# R7FA6M5BH register map
Vendor: Renesas Electronics Corporation; Series: RA6; File version: 1.20.01
CPU: CM33 r0p4, little endian, MPU, FPU, VTOR, 4 interrupt priority bits, 96 interrupts
Registers are 32-bit, read-write, reset 0x0 unless marked. A register's access mark holds for its fields unless they carry their own. Offsets are from the block's base; [hi:lo] are bit positions; {n}, {i} and the like mark numbered series; 'fields as' and 'values as' point back to an identical list.

## CANFD (part 1 of 2)
Base 0x400B0000
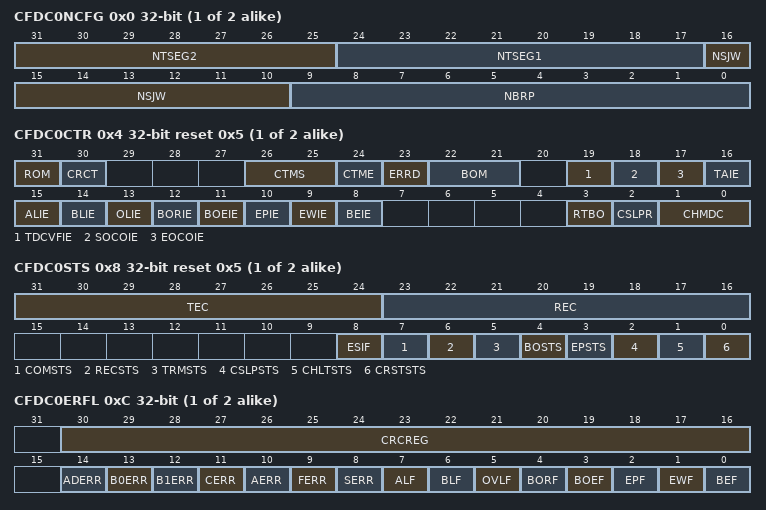
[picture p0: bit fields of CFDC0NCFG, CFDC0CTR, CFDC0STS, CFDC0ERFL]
{0x0+0x10*i} CFDC{i}NCFG (i=0..1) — Channel {i} Nominal Bitrate Configuration Register
  [31:25] NTSEG2 — Timing Segment 2
  [24:17] NTSEG1 — Timing Segment 1
  [16:10] NSJW — Resynchronization Jump Width
  [9:0] NBRP — Channel Nominal Baud Rate Prescaler
{0x4+0x10*i} CFDC{i}CTR (i=0..1) reset 0x5 — Channel {i} Control Registers
  [31] ROM — Restricted Operation Mode
    0=Restricted operation mode disabled; 1=Restricted operation mode enabled
  [30] CRCT — CRC Error Test
    0=First data bit of reception stream not inverted; 1=First data bit of reception stream inverted
  [26:25] CTMS — Channel Test Mode Select
    0=Basic test mode; 1=Listen-only mode; 2=Self-test mode 0 (External loopback mode); 3=Self-test mode 1 (Internal loopback mode)
  [24] CTME — Channel Test Mode Enable
    0=Channel test mode disabled; 1=Channel test mode enabled
  [23] ERRD — Channel Error Display
    0=Only the first set of error codes displayed; 1=Accumulated error codes displayed
  [22:21] BOM — Channel Bus-Off Mode
    0=Normal mode (comply with ISO 11898-1); 1=Entry to Halt mode automatically at bus-off start; 2=Entry to Halt mode automatically at bus-off end; 3=Entry to Halt mode (during bus-off recovery period) by software
  [19] TDCVFIE — Transceiver Delay Compensation Violation Interrupt Enable
    0=Transceiver delay compensation violation interrupt disabled; 1=Transceiver delay compensation violation interrupt enabled
  [18] SOCOIE — Successful Occurrence Counter Overflow Interrupt Enable
    0=Successful occurrence counter overflow interrupt disabled; 1=Successful occurrence counter overflow interrupt enabled
  [17] EOCOIE — Error Occurrence Counter Overflow Interrupt Enable
    0=Error occurrence counter overflow interrupt disabled; 1=Error occurrence counter overflow interrupt enabled
  [16] TAIE — Transmission Abort Interrupt Enable
    0=TX abort interrupt disabled; 1=TX abort interrupt enabled
  [15] ALIE — Arbitration Lost Interrupt Enable
    0=Arbitration lost interrupt disabled; 1=Arbitration lost interrupt enabled
  [14] BLIE — Bus Lock Interrupt Enable
    0=Bus lock interrupt disabled; 1=Bus lock interrupt enabled
  [13] OLIE — Overload Interrupt Enable
    0=Overload interrupt disabled; 1=Overload interrupt enabled
  [12] BORIE — Bus-Off Recovery Interrupt Enable
    0=Bus-off recovery interrupt disabled; 1=Bus-off recovery interrupt enabled
  [11] BOEIE — Bus-Off Entry Interrupt Enable
    0=Bus-off entry interrupt disabled; 1=Bus-off entry interrupt enabled
  [10] EPIE — Error Passive Interrupt Enable
    0=Error passive interrupt disabled; 1=Error passive interrupt enabled
  [9] EWIE — Error Warning Interrupt Enable
    0=Error warning interrupt disabled; 1=Error warning interrupt enabled
  [8] BEIE — Bus Error Interrupt Enable
    0=Bus error interrupt disabled; 1=Bus error interrupt enabled
  [3] RTBO — Return from Bus-Off
    0=Channel is not forced to return from bus-off; 1=Channel is forced to return from bus-off
  [2] CSLPR — Channel Sleep Request
    0=Channel sleep request disabled; 1=Channel sleep request enabled
  [1:0] CHMDC — Channel Mode Control
    0=Channel operation mode request; 1=Channel reset request; 2=Channel halt request; 3=Keep current value
{0x8+0x10*i} CFDC{i}STS (i=0..1) reset 0x5 — Channel {i} Status Registers
  [31:24] TEC ro — Transmission Error Count
  [23:16] REC ro — Reception Error Count
  [8] ESIF — Error State Indication Flag
    0=No CANFD message has been received when the ESI flag was set; 1=At least one CANFD message was received when the ESI flag was set
  [7] COMSTS ro — Channel Communication Status
    0=Channel is not ready for communication; 1=Channel is ready for communication
  [6] RECSTS ro — Channel Receive Status
    0=Channel is not receiving; 1=Channel is receiving
  [5] TRMSTS ro — Channel Transmit Status
    0=Channel is not transmitting; 1=Channel is transmitting
  [4] BOSTS ro — Channel Bus-Off Status
    0=Channel not in bus-off state; 1=Channel in bus-off state
  [3] EPSTS ro — Channel Error Passive Status
    0=Channel not in error passive state; 1=Channel in error passive state
  [2] CSLPSTS ro — Channel Sleep Status
    0=Channel not in Sleep mode; 1=Channel in Sleep mode
  [1] CHLTSTS ro — Channel Halt Status
    0=Channel not in Halt mode; 1=Channel in Halt mode
  [0] CRSTSTS ro — Channel Reset Status
    0=Channel not in Reset mode; 1=Channel in Reset mode
{0xC+0x10*i} CFDC{i}ERFL (i=0..1) — Channel {i} Error Flag Registers
  [30:16] CRCREG ro — CRC Register value
  [14] ADERR — Acknowledge Delimiter Error
    0=Channel acknowledge delimiter error not detected; 1=Channel acknowledge delimiter error detected
  [13] B0ERR — Bit 0 Error
    0=Channel bit 0 error not detected; 1=Channel bit 0 error detected
  [12] B1ERR — Bit 1 Error
    0=Channel bit 1 error not detected; 1=Channel bit 1 error detected
  [11] CERR — CRC Error
    0=Channel CRC error not detected; 1=Channel CRC error detected
  [10] AERR — Acknowledge Error
    0=Channel acknowledge error not detected; 1=Channel acknowledge error detected
  [9] FERR — Form Error
    0=Channel form error not detected; 1=Channel form error detected
  [8] SERR — Stuff Error
    0=Channel stuff error not detected; 1=Channel stuff error detected
  [7] ALF — Arbitration Lost Flag
    0=Channel arbitration lost not detected; 1=Channel arbitration lost detected
  [6] BLF — Bus Lock Flag
    0=Channel bus lock not detected; 1=Channel bus lock detected
  [5] OVLF — Overload Flag
    0=Channel overload not detected; 1=Channel overload detected
  [4] BORF — Bus-Off Recovery Flag
    0=Channel bus-off recovery not detected; 1=Channel bus-off recovery detected
  [3] BOEF — Bus-Off Entry Flag
    0=Channel bus-off entry not detected; 1=Channel bus-off entry detected
  [2] EPF — Error Passive Flag
    0=Channel error passive not detected; 1=Channel error passive detected
  [1] EWF — Error Warning Flag
    0=Channel error warning not detected; 1=Channel error warning detected
  [0] BEF — Bus Error Flag
    0=Channel bus error not detected; 1=Channel bus error detected
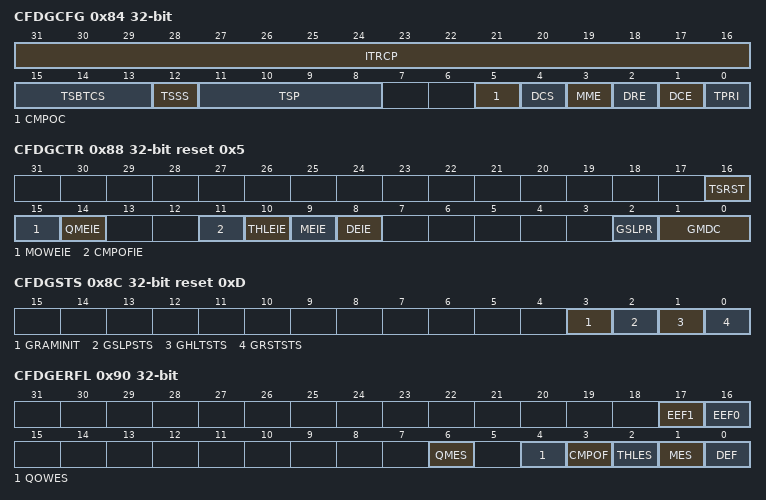
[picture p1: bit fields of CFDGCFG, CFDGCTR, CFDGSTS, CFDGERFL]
0x84 CFDGCFG — Global Configuration Register
  [31:16] ITRCP — Interval Timer Reference Clock Prescaler
  [15:13] TSBTCS — Timestamp Bit Time Channel Select
    0=Select clock from channel 0; 1=Select clock from channel 1; other=Others (Setting prohibited)
  [12] TSSS — Timestamp Source Select
    0=Source clock for timestamp counter is peripheral clock; 1=Source clock for timestamp counter is bit time clock
  [11:8] TSP — Timestamp Prescaler
  [5] CMPOC — CAN-FD Message Payload Overflow Configuration
    0=Message is rejected; 1=Message payload is cut to fit to configured message size
  [4] DCS — Data Link Controller Clock Select
    0=Internal clean clock; 1=External clock source connected to CANMCLK pin
  [3] MME — Mirror Mode Enable
    0=Mirror mode disabled; 1=Mirror mode enabled
  [2] DRE — DLC Replacement Enable
    0=DLC replacement disabled; 1=DLC replacement enabled
  [1] DCE — DLC Check Enable
    0=DLC check disabled; 1=DLC check enabled
  [0] TPRI — Transmission Priority
    0=ID priority; 1=Message buffer number priority
0x88 CFDGCTR reset 0x5 — Global Control Register
  [16] TSRST — Timestamp Reset
    0=Timestamp not reset; 1=Timestamp reset
  [15] MOWEIE — GW FIFO Message Overwrite Error Interrupt Enable
    0=GW FIFO message overwrite error interrupt disabled; 1=GW FIFO message overwrite error interrupt enabled
  [14] QMEIE — TXQ Message Lost Error Interrupt Enable
    0=TXQ message lost error interrupt disabled; 1=TXQ message lost error interrupt enabled
  [11] CMPOFIE — CANFD Message Payload Overflow Flag Interrupt Enable
    0=CANFD message payload overflow flag interrupt disabled; 1=CANFD message payload overflow flag interrupt enabled
  [10] THLEIE — TX History List Entry Lost Interrupt Enable
    0=TX history list entry lost interrupt disabled; 1=TX history list entry lost interrupt enabled
  [9] MEIE — Message Lost Error Interrupt Enable
    0=Message lost error interrupt disabled; 1=Message lost error interrupt enabled
  [8] DEIE — DLC Check Interrupt Enable
    0=DLC check interrupt disabled; 1=DLC check interrupt enabled
  [2] GSLPR — Global Sleep Request
    0=Global sleep request disabled; 1=Global sleep request enabled
  [1:0] GMDC — Global Mode Control
    0=Global operation mode request; 1=Global reset mode request; 2=Global halt mode request; 3=Keep current value
0x8C CFDGSTS ro reset 0xD — Global Status Register
  [3] GRAMINIT — Global RAM Initialization
    0=RAM initialization is complete; 1=RAM initialization is ongoing
  [2] GSLPSTS — Global Sleep Status
    0=Not in Sleep mode; 1=In Sleep mode
  [1] GHLTSTS — Global Halt Status
    0=Not in Halt mode; 1=In Halt mode
  [0] GRSTSTS — Global Reset Status
    0=Not in Reset mode; 1=In Reset mode
0x90 CFDGERFL — Global Error Flag Register
  [17] EEF1 — ECC Error Flag for Channel 1
    0=ECC error not detected during TX-SCAN; 1=ECC error detected during TX-SCAN
  [16] EEF0 — ECC Error Flag for Channel 0
    values as EEF1
  [6] QMES ro — TXQ Message Lost Error Status
    0=TXQ message lost error not detected; 1=TXQ message lost error detected
  [4] QOWES ro — TXQ Message Overwrite Error Status
    0=TXQ message overwrite error not detected; 1=TXQ message overwrite error detected
  [3] CMPOF — CANFD Message Payload Overflow Flag
    0=CANFD message payload overflow not detected; 1=CANFD message payload overflow detected
  [2] THLES ro — TX History List Entry Lost Error Status
    0=TX history list entry lost error not detected; 1=TX history list entry lost error detected
  [1] MES ro — Message Lost Error Status
    0=Message lost error not detected; 1=Message lost error detected
  [0] DEF — DLC Error Flag
    0=DLC error not detected; 1=DLC error detected
0x94 CFDGTSC ro — Global Timestamp Counter Register
  [15:0] TS — Timestamp value
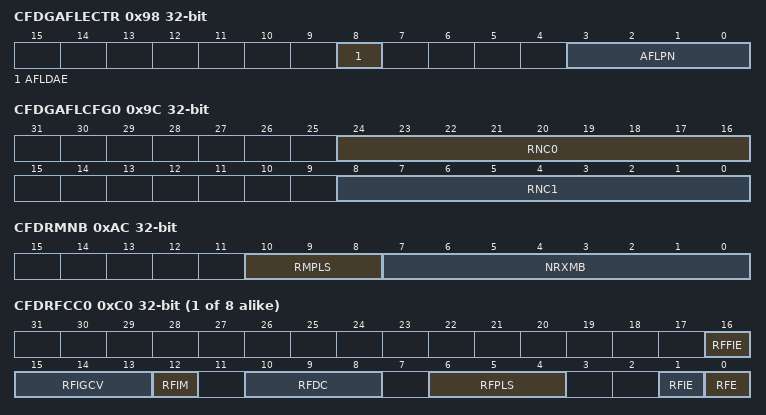
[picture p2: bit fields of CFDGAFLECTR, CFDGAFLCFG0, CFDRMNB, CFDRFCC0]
0x98 CFDGAFLECTR — Global Acceptance Filter List Entry Control Register
  [8] AFLDAE — Acceptance Filter List Data Access Enable
    0=Acceptance Filter List data access disabled; 1=Acceptance Filter List data access enabled
  [3:0] AFLPN — Acceptance Filter List Page Number
0x9C CFDGAFLCFG0 — Global Acceptance Filter List Configuration Register 0
  [24:16] RNC0 — Rule Number for Channel 0
  [8:0] RNC1 — Rule Number for Channel 1
0xAC CFDRMNB — RX Message Buffer Number Register
  [10:8] RMPLS — Reception Message Buffer Payload Data Size
    0=8 bytes; 1=12 bytes; 2=16 bytes; 3=20 bytes; 4=24 bytes; 5=32 bytes; 6=48 bytes; 7=64 bytes
  [7:0] NRXMB — Number of RX Message Buffers
0xB0 CFDRMND0 — RX Message Buffer New Data Register 0
  [31:0] RMNS — RX Message Buffer New Data Status
    0=New data not stored in corresponding RX message buffer; 1=New data stored in corresponding RX message buffer
{0xC0+4i} CFDRFCC{i} (i=0..7) — RX FIFO Configuration/Control Registers {i}
  [16] RFFIE — RX FIFO Full Interrupt Enable
    0=FIFO interrupt generation disabled; 1=FIFO interrupt generation enabled
  [15:13] RFIGCV — RX FIFO Interrupt Generation Counter Value
    0=Interrupt generated when FIFO is 1/8th full; 1=Interrupt generated when FIFO is 1/4th full; 2=Interrupt generated when FIFO is 3/8th full; 3=Interrupt generated when FIFO is 1/2 full; 4=Interrupt generated when FIFO is 5/8th full; 5=Interrupt generated when FIFO is 3/4th full; 6=Interrupt generated when FIFO is 7/8th full; 7=Interrupt generated when FIFO is full
  [12] RFIM — RX FIFO Interrupt Mode
    0=Interrupt generated when RX FIFO counter reaches RFIGCV value from values smaller than RFIGCV; 1=Interrupt generated at the end of every received message storage
  [10:8] RFDC — RX FIFO Depth Configuration
    0=FIFO Depth = 0 message; 1=FIFO Depth = 4 messages; 2=FIFO Depth = 8 messages; 3=FIFO Depth = 16 messages; 4=FIFO Depth = 32 essages; 5=FIFO Depth = 48 messages; 6=FIFO Depth = 64 messages; 7=FIFO Depth = 128 messages
  [6:4] RFPLS — Rx FIFO Payload Data Size Configuration
    values as CFDRMNB.RMPLS
  [1] RFIE — RX FIFO Interrupt Enable
    values as RFFIE
  [0] RFE — RX FIFO Enable
    0=FIFO disabled; 1=FIFO enabled
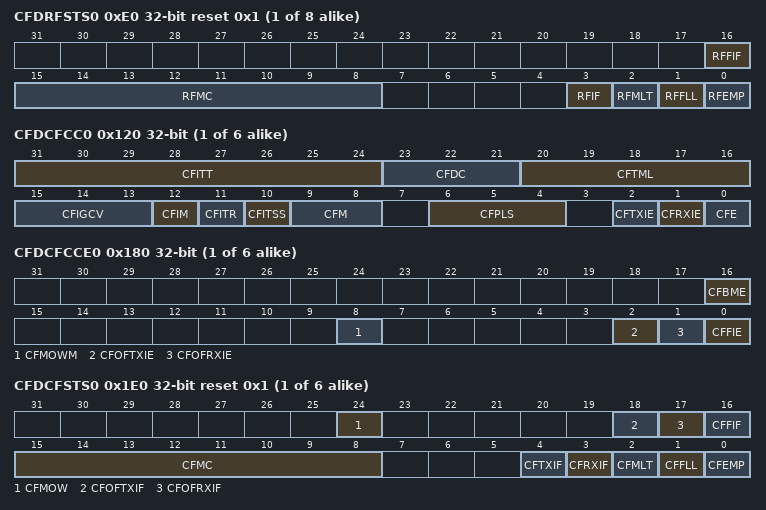
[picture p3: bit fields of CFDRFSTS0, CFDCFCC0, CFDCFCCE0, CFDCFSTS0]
{0xE0+4i} CFDRFSTS{i} (i=0..7) reset 0x1 — RX FIFO Status Registers {i}
  [16] RFFIF — RX FIFO Full Interrupt Flag
    0=FIFO full interrupt condition not satisfied; 1=FIFO full interrupt condition satisfied
  [15:8] RFMC ro — RX FIFO Message Count
  [3] RFIF — RX FIFO Interrupt Flag
    0=FIFO interrupt condition not satisfied; 1=FIFO interrupt condition satisfied
  [2] RFMLT — RX FIFO Message Lost
    0=No message lost in FIFO; 1=FIFO message lost
  [1] RFFLL ro — RX FIFO Full
    0=FIFO not full; 1=FIFO full
  [0] RFEMP ro — RX FIFO Empty
    0=FIFO not empty; 1=FIFO empty
{0x100+4i} CFDRFPCTR{i} (i=0..7) — RX FIFO Pointer Control Registers {i}
  [7:0] RFPC wo — RX FIFO Pointer Control
{0x120+4i} CFDCFCC{i} (i=0..5) — Common FIFO Configuration/Control Registers {i}
  [31:24] CFITT — Common FIFO Interval Transmission Time
  [23:21] CFDC — Common FIFO Depth Configuration
    0=FIFO Depth = 0 messages; 1=FIFO Depth = 4 messages; 2=FIFO Depth = 8 messages; 3=FIFO Depth = 16 messages; 4=FIFO Depth = 32 messages; 5=FIFO Depth = 48 messages; 6=FIFO Depth = 64 messages; 7=FIFO Depth = 128 messages
  [20:16] CFTML — Common FIFO TX Message Buffer Link
  [15:13] CFIGCV — Common FIFO Interrupt Generation Counter Value
    values as CFDRFCC0.RFIGCV
  [12] CFIM — Common FIFO Interrupt Mode
    0=RX FIFO mode: RX interrupt generated when Common FIFO counter reaches CFIGCV value from a lower value TX FIFO mode: TX interrupt generated when Common FIFO transmits the last message successfully GW FIFO mode: For RX interrupt flag: Interrupt generated when FIFO counter increments and reaches the value configured in CFIGCV For TX interrupt flag: Interrupt generated when FIFO transmits the last message successfully; 1=RX FIFO mode: RX interrupt generated at the end of every received message storage TX FIFO mode: interrupt generated for every successfully transmitted message GW FIFO mode: For RX interrupt flag: Interrupt generated when a message is stored in the FIFO For TX interrupt flag: Interrupt generated when a message is successfully transmitted from the FIFO
  [11] CFITR — Common FIFO Interval Timer Resolution
    0=Reference clock period × 1; 1=Reference clock period × 10
  [10] CFITSS — Common FIFO Interval Timer Source Select
    0=Reference clock (× 1 / × 10 period); 1=Bit time clock of related channel (FIFO is linked to fixed channel)
  [9:8] CFM — Common FIFO Mode
    0=RX FIFO mode; 1=TX FIFO mode; 2=CAN – CAN GW FIFO mode
  [6:4] CFPLS — Common FIFO Payload Data Size Configuration
    values as CFDRMNB.RMPLS
  [2] CFTXIE — Common FIFO TX Interrupt Enable
    0=FIFO interrupt generation disabled for Frame TX; 1=FIFO interrupt generation enabled for Frame TX
  [1] CFRXIE — Common FIFO RX Interrupt Enable
    0=FIFO interrupt generation disabled for Frame RX; 1=FIFO interrupt generation enabled for Frame RX
  [0] CFE — Common FIFO Enable
    0=FIFO disabled; 1=FIFO enabled
{0x180+4i} CFDCFCCE{i} (i=0..5) — Common FIFO Configuration/Control Enhancement Registers {i}
  [16] CFBME — Common FIFO Buffering Mode Enable
    0=Transmission from Common FIFO; 1=Transmission halt from Common FIFO
  [8] CFMOWM — Common FIFO Message Overwrite Mode
    0=Message discarded mode; 1=Message overwrite mode
  [2] CFOFTXIE — Common FIFO One Frame Transmission Interrupt Enable
    0=One Frame TX interrupt generation disabled; 1=One Frame TX interrupt generation enabled
  [1] CFOFRXIE — Common FIFO One Frame Reception Interrupt Enable
    0=One Frame RX interrupt generation disabled; 1=One Frame RX interrupt generation enabled
  [0] CFFIE — Common FIFO Full Interrupt Enable
    0=FIFO Interrupt generation disabled; 1=FIFO Interrupt generation enabled
{0x1E0+4i} CFDCFSTS{i} (i=0..5) reset 0x1 — Common FIFO Status Registers {i}
  [24] CFMOW — Common FIFO Message Overwrite
    0=No message overwrite occurred in FIFO; 1=Message overwrite occurred in FIFO
  [18] CFOFTXIF — Common FIFO One Frame Transmission Interrupt Flag
  [17] CFOFRXIF — Common FIFO One Frame Reception Interrupt Flag
  [16] CFFIF — Common FIFO Full Interrupt Flag
    0=Interrupt condition not satisfied for FIFO full interrupt; 1=Interrupt condition satisfied for FIFO full interrupt
  [15:8] CFMC ro — Common FIFO Message Count
  [4] CFTXIF — Common TX FIFO Interrupt Flag
    0=FIFO interrupt condition not satisfied after frame transmission; 1=FIFO Interrupt condition satisfied after frame transmission
  [3] CFRXIF — Common RX FIFO Interrupt Flag
    0=FIFO interrupt condition not satisfied after frame reception; 1=FIFO interrupt condition satisfied after frame reception
  [2] CFMLT — Common FIFO Message Lost
    0=Number of message lost in FIFO; 1=FIFO message lost
  [1] CFFLL ro — Common FIFO Full
    0=FIFO not full; 1=FIFO full
  [0] CFEMP ro — Common FIFO Empty
    0=FIFO not empty; 1=FIFO empty
{0x240+4i} CFDCFPCTR{i} (i=0..5) — Common FIFO Pointer Control Registers {i}
  [7:0] CFPC wo — Common FIFO Pointer Control
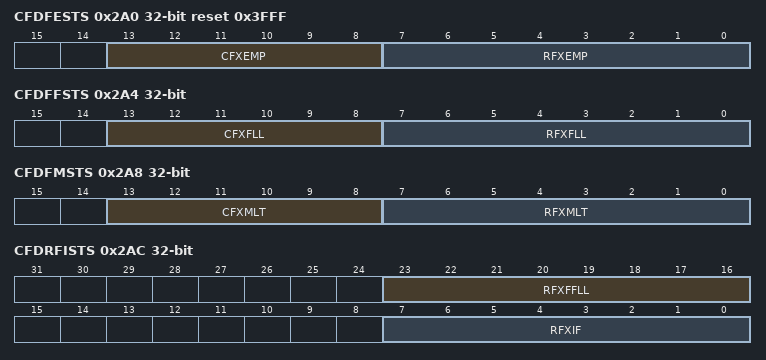
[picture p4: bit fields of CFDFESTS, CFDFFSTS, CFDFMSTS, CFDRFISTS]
0x2A0 CFDFESTS ro reset 0x3FFF — FIFO Empty Status Register
  [13:8] CFXEMP — Common FIFO Empty Status
    0=Corresponding FIFO not empty; 1=Corresponding FIFO empty
  [7:0] RFXEMP — RX FIFO Empty Status
    0=Corresponding FIFO not empty; 1=Corresponding FIFO empty
0x2A4 CFDFFSTS ro — FIFO Full Status Register
  [13:8] CFXFLL — Common FIFO Full Status
    0=Corresponding FIFO not full; 1=Corresponding FIFO full
  [7:0] RFXFLL — RX FIFO Full Status
    0=Corresponding FIFO not full; 1=Corresponding FIFO full
0x2A8 CFDFMSTS ro — FIFO Message Lost Status Register
  [13:8] CFXMLT — Common FIFO Message Lost Status
    0=Corresponding FIFO Message Lost flag not set; 1=Corresponding FIFO Message Lost flag set
  [7:0] RFXMLT — RX FIFO Message Lost Status
    values as CFXMLT
0x2AC CFDRFISTS — RX FIFO Interrupt Flag Status Register
  [23:16] RFXFFLL ro — RX FIFO[x] Interrupt Full Flag Status
    0=Corresponding RX FIFO Interrupt Full flag not set; 1=Corresponding RX FIFO Interrupt Full flag set
  [7:0] RFXIF ro — RX FIFO[x] Interrupt Flag Status
    0=Corresponding RX FIFO Interrupt flag not set; 1=Corresponding RX FIFO Interrupt flag set
0x2B0 CFDCFRISTS — Common FIFO RX Interrupt Flag Status Register
  [5:0] CFXRXIF ro — Common FIFO RX Interrupt Flag Status
    0=Corresponding Common FIFO RX Interrupt flag is not set; 1=Corresponding Common FIFO RX Interrupt flag is set
0x2B4 CFDCFTISTS — Common FIFO TX Interrupt Flag Status Register
  [5:0] CFXTXIF ro — Common FIFO [x] TX Interrupt Flag Status
    0=Corresponding Common FIFO TX Interrupt flag is not set; 1=Corresponding Common FIFO TX Interrupt flag is set
0x2B8 CFDCFOFRISTS ro — Common FIFO One Frame RX Interrupt Flag Status Register
  [5:0] CFXOFRXIF — Common FIFO One Frame RX Interrupt Flag Status
    0=Corresponding Common FIFO One Frame RX Interrupt flag is not set; 1=Corresponding Common FIFO One Frame RX Interrupt flag is set
0x2BC CFDCFOFTISTS ro — Common FIFO One Frame TX Interrupt Flag Status Register
  [5:0] CFXOFTXIF — Common FIFO One Frame TX Interrupt Flag Status
    0=Corresponding Common FIFO One Frame TX Interrupt flag is not set; 1=Corresponding Common FIFO One Frame TX Interrupt flag is set
0x2C0 CFDCFMOWSTS ro — Common FIFO Message Over Write Status Register
  [5:0] CFXMOW — Common FIFO Massage Overwrite Status
    0=Corresponding FIFO Overwrite flag is not set; 1=Corresponding FIFO Overwrite flag is set
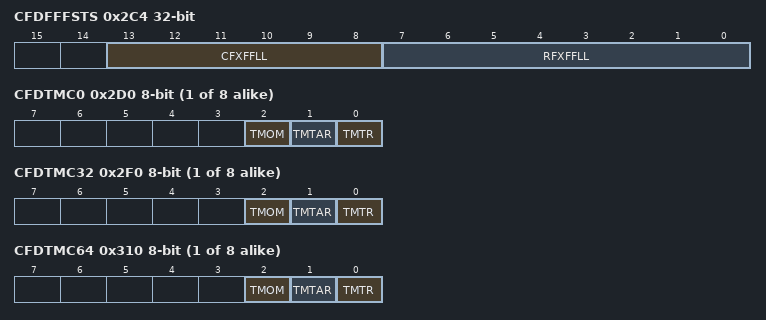
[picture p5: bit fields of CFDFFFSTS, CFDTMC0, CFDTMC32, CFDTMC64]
0x2C4 CFDFFFSTS ro — FIFO FDC Full Status Register
  [13:8] CFXFFLL — COMMON FIFO FDC Level Full Status
    0=Corresponding FIFO full interrupt not set; 1=Corresponding FIFO full interrupt is set
  [7:0] RFXFFLL — RX FIFO FDC Level Full Status
    values as CFXFFLL
{0x2D0+i} CFDTMC{i} (i=0..7) 8-bit — TX Message Buffer Control Registers {i}
  [2] TMOM — TX Message Buffer One-shot Mode
    0=TX message buffer not configured in one-shot mode; 1=TX message buffer configured in one-shot mode
  [1] TMTAR — TX Message Buffer Transmission Abort Request
    0=TX message buffer transmission request abort not requested; 1=TX message buffer transmission request abort requested
  [0] TMTR — TX Message Buffer Transmission Request
    0=TX Message buffer transmission not requested; 1=TX message buffer transmission requested
{0x2D0+i} CFDTMC{i} (i=32..39) 8-bit — TX Message Buffer Control Registers {i}
  fields as CFDTMC0
{0x2D0+i} CFDTMC{i} (i=64..71) 8-bit — TX Message Buffer Control Registers {i}
  fields as CFDTMC0
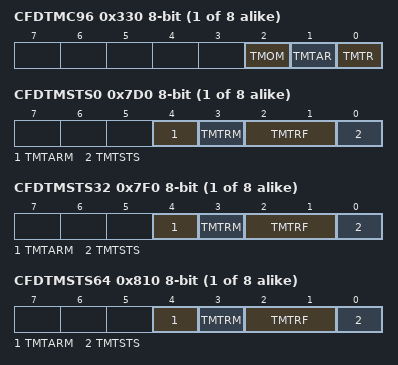
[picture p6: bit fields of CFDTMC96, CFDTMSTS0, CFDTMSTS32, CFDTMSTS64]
{0x2D0+i} CFDTMC{i} (i=96..103) 8-bit — TX Message Buffer Control Registers {i}
  fields as CFDTMC0
{0x7D0+i} CFDTMSTS{i} (i=0..7) 8-bit — TX Message Buffer Status Registers {i}
  [4] TMTARM ro — TX Message Buffer Transmission Abort Request Mirrored
    values as CFDTMC0.TMTAR
  [3] TMTRM ro — TX Message Buffer Transmission Request Mirrored
    0=TX message buffer transmission not requested; 1=TX message buffer transmission requested
  [2:1] TMTRF — TX Message Buffer Transmission Result Flag
    0=No result; 1=Transmission aborted from the TX message buffer; 2=Transmission successful from the TX message buffer and transmission abort was not requested; 3=Transmission successful from the TX message buffer and transmission abort was requested
  [0] TMTSTS ro — TX Message Buffer Transmission Status
    0=No on-going transmission; 1=On-going transmission
{0x7D0+i} CFDTMSTS{i} (i=32..39) 8-bit — TX Message Buffer Status Registers {i}
  fields as CFDTMSTS0
{0x7D0+i} CFDTMSTS{i} (i=64..71) 8-bit — TX Message Buffer Status Registers {i}
  fields as CFDTMSTS0
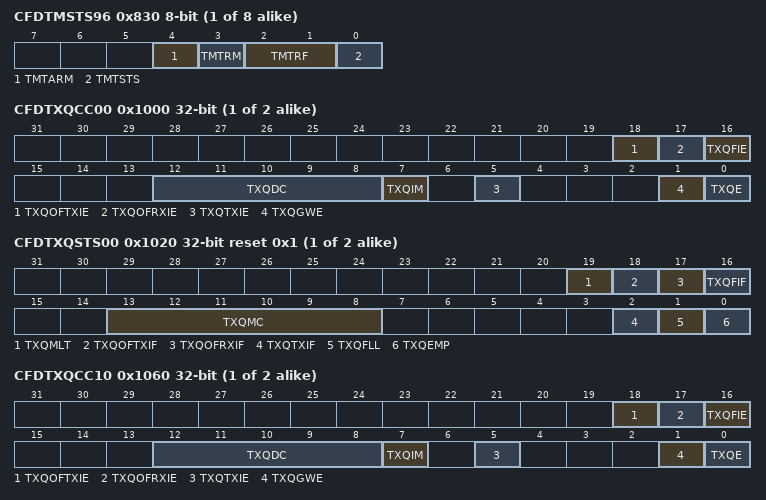
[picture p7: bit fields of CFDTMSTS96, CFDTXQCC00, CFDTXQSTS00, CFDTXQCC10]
{0x7D0+i} CFDTMSTS{i} (i=96..103) 8-bit — TX Message Buffer Status Registers {i}
  fields as CFDTMSTS0
{0xCD0+4i} CFDTMTRSTS{i} (i=0..3) ro — TX Message Buffer Transmission Request Status Register {i}
  [7:0] CFDTMTRSTS — TX Message Buffer Transmission Request Status
    0=Transmission not requested for corresponding TX message buffer; 1=Transmission requested for corresponding TX message buffer
{0xD70+4i} CFDTMTARSTS{i} (i=0..3) ro — TX Message Buffer Transmission Abort Request Status Register {i}
  [7:0] CFDTMTARSTS — TX Message Buffer Transmission Abort Request Status
    0=Transmission abort not requested for corresponding TX message buffer; 1=Transmission abort requested for corresponding TX message buffer
{0xE10+4i} CFDTMTCSTS{i} (i=0..3) ro — TX Message Buffer Transmission Completion Status Register {i}
  [7:0] CFDTMTCSTS — TX Message Buffer Transmission Completion Status
    0=Transmission not complete for corresponding TX message buffer; 1=Transmission completed for corresponding TX message buffer
{0xEB0+4i} CFDTMTASTS{i} (i=0..3) ro — TX Message Buffer Transmission Abort Status Register {i}
  [7:0] CFDTMTASTS — TX Message Buffer Transmission Abort Status
    0=Transmission not aborted for corresponding TX message buffer; 1=Transmission aborted for corresponding TX message buffer
{0xF50+4i} CFDTMIEC{i} (i=0..3) — TX Message Buffer Interrupt Enable Configuration Register {i}
  [7:0] TMIE — TX Message Buffer Interrupt Enable
    0=TX message buffer interrupt disabled for corresponding TX message buffer; 1=TX message buffer interrupt enabled for corresponding TX message buffer
{0x1000+4i} CFDTXQCC0{i} (i=0..1) — TX Queue Configuration/Control Registers 0{i}
  [18] TXQOFTXIE — TXQ One Frame Transmission Interrupt Enable
    values as CFDCFCCE0.CFOFTXIE
  [17] TXQOFRXIE — TXQ One Frame Reception Interrupt Enable
    values as CFDCFCCE0.CFOFRXIE
  [16] TXQFIE — TXQ Full Interrupt Enable
    0=TX Queue full interrupt generation disabled; 1=TX Queue full interrupt generation enabled
  [12:8] TXQDC — TX Queue Depth Configuration
  [7] TXQIM — TX Queue Interrupt Mode
    0=When the last message is successfully transmitted; 1=At every successful transmission
  [5] TXQTXIE — TX Queue TX Interrupt Enable
    0=TX Queue TX interrupt disabled; 1=TX Queue TX interrupt enabled
  [1] TXQGWE — TX Queue Gateway Mode Enable
    0=TX Queue GW mode disabled; 1=TX Queue GW mode enabled
  [0] TXQE — TX Queue Enable
    0=TX Queue disabled; 1=TX Queue enabled
{0x1020+4i} CFDTXQSTS0{i} (i=0..1) reset 0x1 — TX Queue Status Registers 0{i}
  [19] TXQMLT — TXQ Message Lost
    0=No message lost in TXQ; 1=TXQ message lost
  [18] TXQOFTXIF — TXQ One Frame Transmission Interrupt Flag
  [17] TXQOFRXIF — TXQ One Frame Reception Interrupt Flag
  [16] TXQFIF — TXQ Full Interrupt Flag
  [13:8] TXQMC ro — TX Queue Message Count
  [2] TXQTXIF — TX Queue TX Interrupt Flag
    0=TX Queue interrupt condition not satisfied after a frame TX; 1=TX Queue interrupt condition satisfied after a frame TX
  [1] TXQFLL ro — TX Queue Full
    0=TX Queue not full; 1=TX Queue full
  [0] TXQEMP ro — TX Queue Empty
    0=TX Queue not empty; 1=TX Queue empty
{0x1040+4i} CFDTXQPCTR0{i} (i=0..1) — TX Queue Pointer Control Registers 0{i}
  [7:0] TXQPC wo — TX Queue Pointer Control
{0x1060+4i} CFDTXQCC1{i} (i=0..1) — TX Queue Configuration/Control Registers 1{i}
  fields as CFDTXQCC00
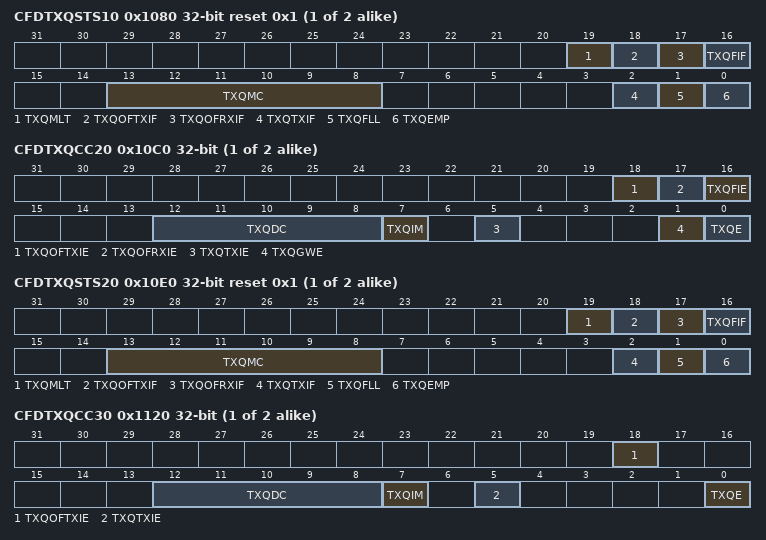
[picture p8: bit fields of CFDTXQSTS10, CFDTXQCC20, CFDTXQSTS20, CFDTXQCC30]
{0x1080+4i} CFDTXQSTS1{i} (i=0..1) reset 0x1 — TX Queue Status Registers 1{i}
  fields as CFDTXQSTS00
{0x10A0+4i} CFDTXQPCTR1{i} (i=0..1) — TX Queue Pointer Control Registers 1{i}
  [7:0] TXQPC wo — TX Queue Pointer Control
{0x10C0+4i} CFDTXQCC2{i} (i=0..1) — TX Queue Configuration/Control Registers 2{i}
  fields as CFDTXQCC00
{0x10E0+4i} CFDTXQSTS2{i} (i=0..1) reset 0x1 — TX Queue Status Registers 2{i}
  fields as CFDTXQSTS00
{0x1100+4i} CFDTXQPCTR2{i} (i=0..1) — TX Queue Pointer Control Registers 2{i}
  [7:0] TXQPC wo — TX Queue Pointer Control
{0x1120+4i} CFDTXQCC3{i} (i=0..1) — TX Queue Configuration/Control Registers 3{i}
  [18] TXQOFTXIE — TXQ One Frame Transmission Interrupt Enable
    values as CFDCFCCE0.CFOFTXIE
  [12:8] TXQDC — TX Queue Depth Configuration
  [7] TXQIM — TX Queue Interrupt Mode
    values as CFDTXQCC00.TXQIM
  [5] TXQTXIE — TX Queue TX Interrupt Enable
    values as CFDTXQCC00.TXQTXIE
  [0] TXQE — TX Queue Enable
    0=TX Queue disabled; 1=TX Queue enabled
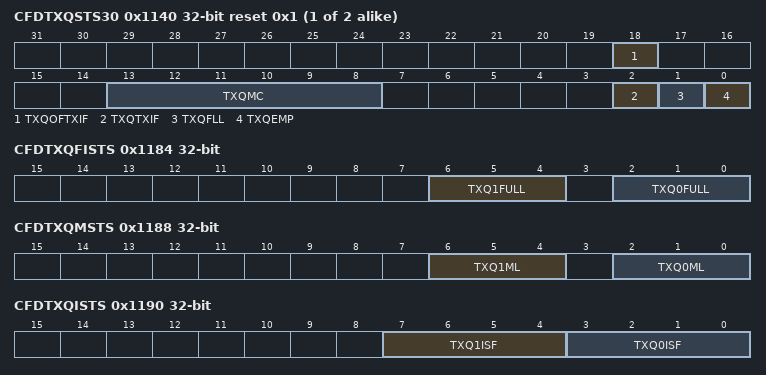
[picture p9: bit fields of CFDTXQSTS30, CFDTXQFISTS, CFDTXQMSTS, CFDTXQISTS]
{0x1140+4i} CFDTXQSTS3{i} (i=0..1) reset 0x1 — TX Queue Status Registers 3{i}
  [18] TXQOFTXIF — TXQ One Frame Transmission Interrupt Flag
  [13:8] TXQMC ro — TX Queue Message Count
  [2] TXQTXIF — TX Queue TX Interrupt Flag
    values as CFDTXQSTS00.TXQTXIF
  [1] TXQFLL ro — TX Queue Full
    0=TX Queue not full; 1=TX Queue full
  [0] TXQEMP ro — TX Queue Empty
    0=TX Queue not empty; 1=TX Queue empty
{0x1160+4i} CFDTXQPCTR3{i} (i=0..1) — TX Queue Pointer Control Registers 3{i}
  [7:0] TXQPC wo — TX Queue Pointer Control
0x1180 CFDTXQESTS ro reset 0xFF — TX Queue Empty Status Register
  [7:0] TXQxEMP — TXQ Empty Status
    0=TXQ not empty; 1=TXQ empty
0x1184 CFDTXQFISTS — TX Queue Full Interrupt Status Register
  [6:4] TXQ1FULL ro — TXQ Full Interrupt Status for Channel 1
    0=TXQ full interrupt is not set; 1=TXQ full interrupt is set
  [2:0] TXQ0FULL ro — TXQ Full Interrupt Status for Channel 0
    0=TXQ full interrupt is not set; 1=TXQ full interrupt is set
0x1188 CFDTXQMSTS — TX Queue Message Lost Status Register
  [6:4] TXQ1ML ro — TXQ Message Lost Status for Channel 1
    0=TXQ message lost flag is not set; 1=TXQ message lost flag is set
  [2:0] TXQ0ML ro — TXQ Message Lost Status for Channel 0
    values as TXQ1ML
0x1190 CFDTXQISTS — TX Queue Interrupt Status Register
  [7:4] TXQ1ISF ro — TXQ Interrupt Status Flag for Channel 1
    0=TXQ Interrupt flag is not set; 1=TXQ Interrupt flag is set
  [3:0] TXQ0ISF ro — TXQ Interrupt Status Flag for Channel 0
    0=TXQ Interrupt flag is not set; 1=TXQ Interrupt flag is set
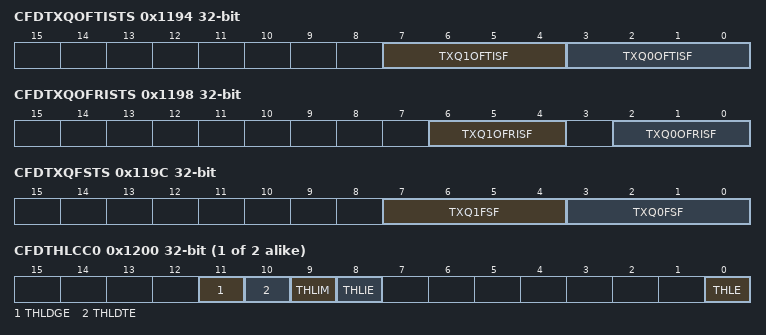
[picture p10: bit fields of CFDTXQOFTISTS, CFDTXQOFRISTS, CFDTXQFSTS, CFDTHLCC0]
0x1194 CFDTXQOFTISTS — TX Queue One Frame TX Interrupt Status Register
  [7:4] TXQ1OFTISF ro — TXQ One Frame TX Interrupt Status Flag for Channel 1
    0=TXQ One Frame TX Interrupt flag is not set; 1=TXQ One Frame TX Interrupt flag is set
  [3:0] TXQ0OFTISF ro — TXQ One Frame TX Interrupt Status Flag for Channel 0
    values as TXQ1OFTISF
0x1198 CFDTXQOFRISTS — TX Queue One Frame RX Interrupt Status Register
  [6:4] TXQ1OFRISF ro — TXQ One Frame RX Interrupt Status Flag
    0=TXQ One Frame RX Interrupt flag is not set; 1=TXQ One Frame RX Interrupt flag is set
  [2:0] TXQ0OFRISF ro — TXQ One Frame RX Interrupt Status Flag
    values as TXQ1OFRISF
0x119C CFDTXQFSTS ro — TX Queue Full Status Register
  [7:4] TXQ1FSF — TXQ Full Status Flag for Channel 1
    0=TXQ Full flag is not set; 1=TXQ Full flag is set
  [3:0] TXQ0FSF — TXQ Full Status Flag for Channel 0
    0=TXQ Full flag is not set; 1=TXQ Full flag is set
{0x1200+4i} CFDTHLCC{i} (i=0..1) — TX History List Configuration/Control Register {i}
  [11] THLDGE — TX History List Dedicated Gateway Enable
    0=Not dedicated Gateway FIFO + Gateway TX Queue; 1=Dedicated Gateway FIFO + Gateway TX Queue
  [10] THLDTE — TX History List Dedicated TX Enable
    0=TX FIFO + TX Queue; 1=Flat TX MB + TX FIFO + TX Queue
  [9] THLIM — TX History List Interrupt Mode
    0=Interrupt generated if TX History List level reaches ¾ of the TX History List depth; 1=Interrupt generated for every successfully stored entry
  [8] THLIE — TX History List Interrupt Enable
    0=TX History List Interrupt disabled; 1=TX History List Interrupt enabled
  [0] THLE — TX History List Enable
    0=TX History List disabled; 1=TX History List enabled
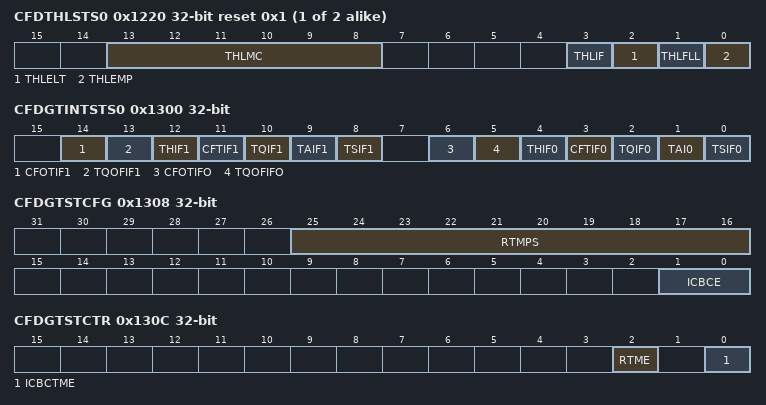
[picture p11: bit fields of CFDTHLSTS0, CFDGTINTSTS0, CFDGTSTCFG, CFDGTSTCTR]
{0x1220+4i} CFDTHLSTS{i} (i=0..1) reset 0x1 — TX History List Status Register {i}
  [13:8] THLMC ro — TX History List Message Count
  [3] THLIF — TX History List Interrupt Flag
    0=TX History List interrupt condition not satisfied; 1=TX History List interrupt condition satisfied
  [2] THLELT — TX History List Entry Lost
    0=No entry lost in TX History List; 1=TX History List entry Lost
  [1] THLFLL ro — TX History List Full
    0=TX History List not full; 1=TX History List full
  [0] THLEMP ro — TX History List Empty
    0=TX History List not empty; 1=TX History List empty
{0x1240+4i} CFDTHLPCTR{i} (i=0..1) — TX History List Pointer Control Registers {i}
  [7:0] THLPC wo — TX History List Pointer Control
0x1300 CFDGTINTSTS0 — Global TX Interrupt Status Register 0
  [14] CFOTIF1 ro — COM FIFO One Frame Transmission Interrupt Flag Channel 1
    0=Channel n COM FIFO One Frame Transmission Interrupt flag not set; 1=Channel n COM FIFO One Frame Transmission Interrupt flag set
  [13] TQOFIF1 ro — TX Queue One Frame Transmission Interrupt Flag Channel 1
    0=Channel n TX Queue One Frame Transmission Interrupt flag not set; 1=Channel n TX Queue One Frame Transmission Interrupt flag set
  [12] THIF1 ro — TX History List Interrupt Channel 1
    0=Channel n TX History List Interrupt flag not set; 1=Channel n TX History List Interrupt flag set
  [11] CFTIF1 ro — COM FIFO TX/GW Mode Interrupt Flag Channel 1
    0=Channel n COM FIFO TX/GW Mode Interrupt flag not set; 1=Channel n COM FIFO TX/GW Mode Interrupt flag set
  [10] TQIF1 ro — TX Queue Interrupt Flag Channel 1
    0=Channel n TX Queue Interrupt flag not set; 1=Channel n TX Queue Interrupt flag set
  [9] TAIF1 ro — TX Abort Interrupt Flag Channel 1
    0=Channel n TX Abort Interrupt flag not set; 1=Channel n TX Abort Interrupt flag set
  [8] TSIF1 ro — TX Successful Interrupt Flag Channel 1
    0=Channel n TX Successful Interrupt flag not set; 1=Channel n TX Successful Interrupt flag set
  [6] CFOTIFO ro — COM FIFO One Frame Transmission Interrupt Flag Channel 0
    values as CFOTIF1
  [5] TQOFIFO ro — TX Queue One Frame Transmission Interrupt Flag Channel 0
    values as TQOFIF1
  [4] THIF0 ro — TX History List Interrupt Channel 0
    values as THIF1
  [3] CFTIF0 ro — COM FIFO TX/GW Mode Interrupt Flag Channel 0
    values as CFTIF1
  [2] TQIF0 ro — TX Queue Interrupt Flag Channel 0
    values as TQIF1
  [1] TAI0 ro — TX Abort Interrupt Flag Channel 0
    values as TAIF1
  [0] TSIF0 ro — TX Successful Interrupt Flag Channel 0
    values as TSIF1
0x1308 CFDGTSTCFG — Global Test Configuration Register
  [25:16] RTMPS — RAM Test Mode Page Select
  [1:0] ICBCE — Channel n Internal CAN Bus Communication Test Mode Enable
    0=Channel n internal CAN bus communication disabled; 1=Channel n internal CAN bus communication enabled
0x130C CFDGTSTCTR — Global Test Control Register
  [2] RTME — RAM Test Mode Enable
    0=RAM test mode disabled; 1=RAM test mode enabled
  [0] ICBCTME — Internal CAN Bus Communication Test Mode Enable
    0=Internal CAN Bus Communication test mode disabled; 1=Internal CAN Bus Communication test mode enabled
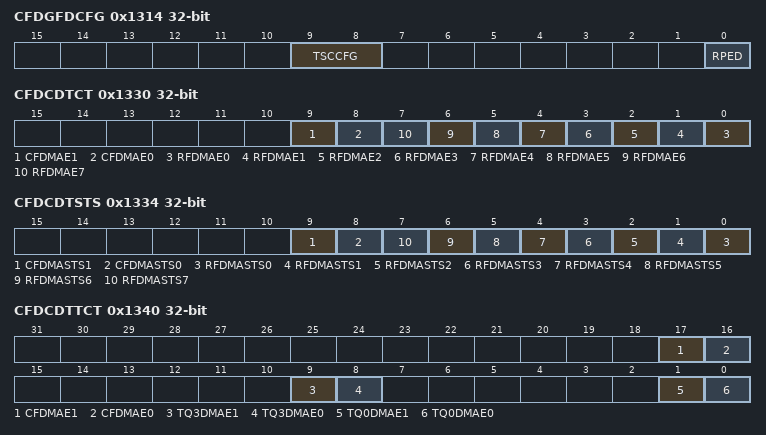
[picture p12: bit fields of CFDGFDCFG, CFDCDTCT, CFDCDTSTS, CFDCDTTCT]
0x1314 CFDGFDCFG — Global FD Configuration Register
  [9:8] TSCCFG — Timestamp Capture Configuration
    0=Timestamp capture at the sample point of SOF (start of frame); 1=Timestamp capture at frame valid indication; 2=Timestamp capture at the sample point of RES bit
  [0] RPED — RES Bit Protocol Exception Disable
    0=Protocol exception event detection enabled; 1=Protocol exception event detection disabled
0x131C CFDGLOCKK wo — Global Lock Key Register
  [15:0] LOCK — Lock Key
0x1330 CFDCDTCT — DMA Transfer Control Register
  [all] fields
    0=DMA transfer request disabled; 1=DMA transfer request enabled
  [9] CFDMAE1 — DMA Transfer Enable for Common FIFO 0 of Channel 1
  [8] CFDMAE0 — DMA Transfer Enable for Common FIFO 0 of Channel 0
  [n] RFDMAE{n} (n=0..7) — DMA Transfer Enable for RXFIFO {n}
0x1334 CFDCDTSTS ro — DMA Transfer Status Register
  [all] fields
    0=DMA transfer stopped; 1=DMA transfer on going
  [9] CFDMASTS1 — DMA Transfer Status only for Common FIFO 0 of Channel 1
  [8] CFDMASTS0 — DMA Transfer Status only for Common FIFO 0 of Channel 0
  [n] RFDMASTS{n} (n=0..7) — DMA Transfer Status for RX FIFO {n}
0x1340 CFDCDTTCT — DMA TX Transfer Control Register
  [all] fields
    0=DMA TX transfer request disabled; 1=DMA TX transfer request enabled
  [17] CFDMAE1 — DMA TX Transfer Enable for Common FIFO 2 of Channel 1
  [16] CFDMAE0 — DMA TX Transfer Enable for Common FIFO 2 of Channel 0
  [9] TQ3DMAE1 — DMA TX Transfer Enable for TXQ 3 of Channel 1
  [8] TQ3DMAE0 — DMA TX Transfer Enable for TXQ 3 of Channel 0
  [1] TQ0DMAE1 — DMA TX Transfer Enable for TXQ 0 of Channel 1
  [0] TQ0DMAE0 — DMA TX Transfer Enable for TXQ 0 of Channel 0
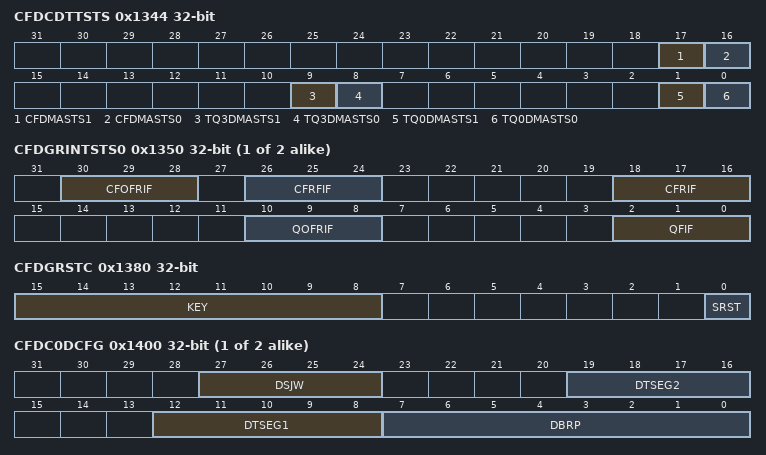
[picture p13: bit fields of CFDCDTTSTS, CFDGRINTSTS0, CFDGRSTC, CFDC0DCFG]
0x1344 CFDCDTTSTS — DMA TX Transfer Status Register
  [all] fields
    0=DMA transfer stopped; 1=DMA transfer enabled
  [17] CFDMASTS1 ro — DMA TX Transfer Status only for Common FIFO 2 of Channel 1
  [16] CFDMASTS0 ro — DMA TX Transfer Status only for Common FIFO 2 of Channel 0
  [9] TQ3DMASTS1 ro — DMA TX Transfer Status for TXQ3 of Channel 1
  [8] TQ3DMASTS0 ro — DMA TX Transfer Status for TXQ3 of Channel 0
  [1] TQ0DMASTS1 ro — DMA TX Transfer Status for TXQ0 of Channel 1
  [0] TQ0DMASTS0 ro — DMA TX Transfer Status for TXQ0 of Channel 0
{0x1350+4i} CFDGRINTSTS{i} (i=0..1) — Global RX Interrupt Status Register {i}
  [30:28] CFOFRIF ro — Common FIFO One Frame RX Interrupt Flag Channel n (n = 0, 1)
    values as CFDCFOFRISTS.CFXOFRXIF
  [26:24] CFRFIF ro — Common FIFO FDC Level Full Interrupt Flag Channel n (n = 0, 1)
    0=Corresponding Common FIFO Full Interrupt flag is not set; 1=Corresponding Common FIFO Full Interrupt flag is set
  [18:16] CFRIF ro — Common FIFO RX Interrupt Flag Channel n (n = 0, 1)
    values as CFDCFRISTS.CFXRXIF
  [10:8] QOFRIF ro — TXQ One Frame RX Interrupt Flag Channel n (n = 0, 1)
    0=Corresponding TXQ One Frame RX Interrupt flag is not set; 1=Corresponding TXQ One Frame RX Interrupt flag is set
  [2:0] QFIF ro — TXQ Full Interrupt Flag Channel n (n = 0, 1)
    0=Corresponding TXQ Full Interrupt flag is not set; 1=Corresponding TXQ Full Interrupt flag is set
0x1380 CFDGRSTC — Global SW reset Register
  [15:8] KEY wo — Key Code
  [0] SRST — SW Reset
    0=Normal state; 1=SW reset state
{0x1400+0x20*i} CFDC{i}DCFG (i=0..1) — Channel {i} Data Bitrate Configuration Register
  [27:24] DSJW — Resynchronization Jump Width
  [19:16] DTSEG2 — Timing Segment 2
  [12:8] DTSEG1 — Timing Segment 1
  [7:0] DBRP — Channel Data Baud Rate Prescaler
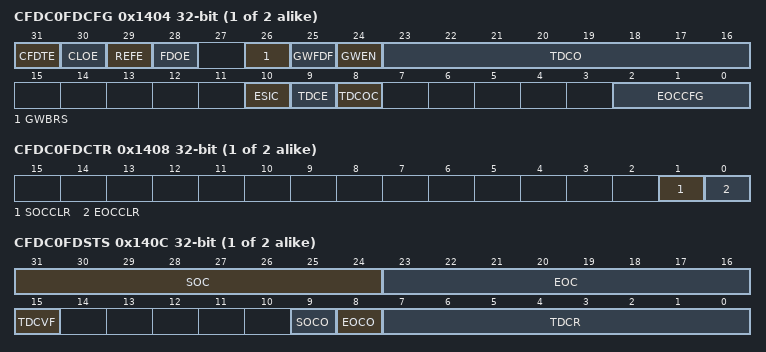
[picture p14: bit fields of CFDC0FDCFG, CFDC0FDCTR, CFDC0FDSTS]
{0x1404+0x20*i} CFDC{i}FDCFG (i=0..1) — Channel {i} CAN-FD Configuration Register
  [31] CFDTE — CAN-FD Frame Distinction Enable
    0=CAN-FD frame distinction disabled; 1=CAN-FD frame distinction enabled
  [30] CLOE — Classical CAN Enable
    0=Classical CAN mode disabled; 1=Classical CAN mode enabled
  [29] REFE — RX Edge Filter Enable
    0=RX edge filter disabled; 1=RX edge filter enabled
  [28] FDOE — FD-Only Enable
    0=FD-only mode disabled; 1=FD-only mode enabled
  [26] GWBRS — Gateway BRS Configuration Bit
    0=Gateway frame is transmitted with BRS = 0; 1=Gateway frame is transmitted with BRS = 1
  [25] GWFDF — Gateway FDF Configuration Bit
    0=Gateway frame is transmitted as Classical CAN frame; 1=Gateway frame is transmitted as CAN-FD frame
  [24] GWEN — CAN2.0, CAN-FD Multi-Gateway Enable
    0=Multi-gateway disabled; 1=Multi-gateway enable
  [23:16] TDCO — Transceiver Delay Compensation Offset
  [10] ESIC — Error State Indication Configuration
    0=The ESI bit in the frame represents the error state of the node itself; 1=The ESI bit in the frame represents the error state of the message buffer if the node itself is not in error passive. If the node is in error passive, then the ESI bit is driven by the node itself.
  [9] TDCE — Transceiver Delay Compensation Enable
    0=Transceiver delay compensation disabled; 1=Transceiver delay compensation enabled
  [8] TDCOC — Transceiver Delay Compensation Offset Configuration
    0=Measured + offset; 1=Offset-only
  [2:0] EOCCFG — Error Occurrence Counter Configuration
    0=All transmitter or receiver CAN frames; 1=All transmitter CAN frames; 2=All receiver CAN frames; 4=Only transmitter or receiver CAN-FD data-phase (fast bits); 5=Only transmitter CAN-FD data-phase (fast bits); 6=Only receiver CAN-FD data-phase (fast bits)
{0x1408+0x20*i} CFDC{i}FDCTR (i=0..1) — Channel {i} CANFD Control Register
  [1] SOCCLR — Successful Occurrence Counter Clear
    0=No successful occurrence counter clear; 1=Clear successful occurrence counter
  [0] EOCCLR — Error Occurrence Counter Clear
    0=No error occurrence counter clear; 1=Clear error occurrence counter
{0x140C+0x20*i} CFDC{i}FDSTS (i=0..1) — Channel {i} CANFD Status Register
  [31:24] SOC ro — Successful occurrence counter
  [23:16] EOC ro — Error Occurrence Counter
  [15] TDCVF — Transceiver Delay Compensation Violation Flag
    0=Transceiver delay compensation violation has not occurred; 1=Transceiver delay compensation violation has occurred
  [9] SOCO — Successful Occurrence Counter Overflow
    0=Successful occurrence counter has not overflowed; 1=Successful occurrence counter has overflowed
  [8] EOCO — Error Occurrence Counter Overflow
    0=Error occurrence counter has not overflowed; 1=Error occurrence counter has overflowed
  [7:0] TDCR ro — Transceiver Delay Compensation Result
